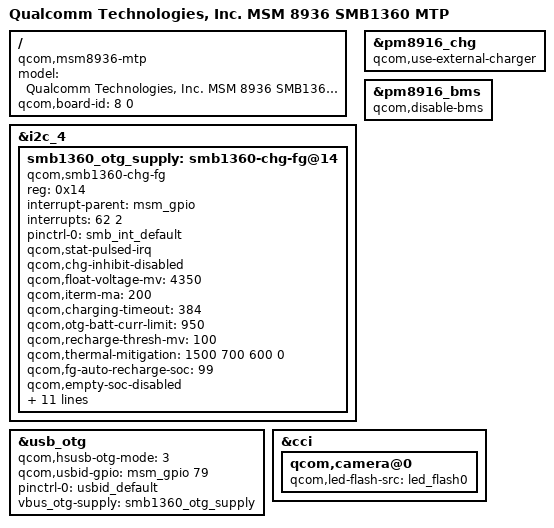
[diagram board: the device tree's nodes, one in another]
/* Copyright (c) 2014, The Linux Foundation. All rights reserved.
*
* This program is free software; you can redistribute it and/or modify
* it under the terms of the GNU General Public License version 2 and
* only version 2 as published by the Free Software Foundation.
*
* This program is distributed in the hope that it will be useful,
* but WITHOUT ANY WARRANTY; without even the implied warranty of
* MERCHANTABILITY or FITNESS FOR A PARTICULAR PURPOSE.  See the
* GNU General Public License for more details.
*/

/dts-v1/;

#include "msm8936.dtsi"
#include "msm8939-mtp.dtsi"
#include "msm8939-audio-internal_codec.dtsi"

/ {
	model = "Qualcomm Technologies, Inc. MSM 8936 SMB1360 MTP";
	compatible = "qcom,msm8936-mtp", "qcom,msm8936", "qcom,mtp";
	qcom,board-id = <8 0>;
};

&i2c_4 {
	smb1360_otg_supply: smb1360-chg-fg@14 {
/* [PLATFORM]-Mod-BEGIN by TCTNB.FLF, PR-790435, 2014/11/12, fix irq blocks booting up*/
/*
		compatible = "qcom,smb1360-chg-fg";
		reg = <0x14>;
		interrupt-parent = <&msm_gpio>;
		interrupts = <62 8>;
		pinctrl-names = "default";
		pinctrl-0 = <&smb_int_default>;
		qcom,charging-disabled;
		qcom,empty-soc-disabled;
		qcom,chg-inhibit-disabled;
		qcom,float-voltage-mv = <4200>;
		qcom,iterm-ma = <200>;
		qcom,recharge-thresh-mv = <100>;
		qcom,thermal-mitigation = <1500 700 600 0>;
		regulator-name = "smb1360_otg_vreg";
*/
        compatible = "qcom,smb1360-chg-fg";
        reg = <0x14>;
        interrupt-parent = <&msm_gpio>;
        interrupts = <62 2>;
        pinctrl-names = "default";
        pinctrl-0 = <&smb_int_default>;
        qcom,stat-pulsed-irq;
        qcom,chg-inhibit-disabled;
        qcom,float-voltage-mv = <4350>;
        qcom,iterm-ma = <200>;
        qcom,charging-timeout = <384>;
        qcom,otg-batt-curr-limit = <950>;
        qcom,recharge-thresh-mv = <100>;
        qcom,thermal-mitigation = <1500 700 600 0>;
        qcom,fg-auto-recharge-soc = <99>;
        qcom,empty-soc-disabled;
        regulator-name = "smb1360_otg_vreg";
        qcom,awake-min-soc;
        qcom,batt-profile-select;
        qcom,smb1360-vadc = <&pm8916_vadc>;
        qcom,batt-id-vref-uv = <1800000>;
        qcom,batt-id-rpullup-kohm = <100>;
        qcom,profile-a-rid-kohm = <33>;
        qcom,profile-b-rid-kohm = <91>;
        qcom,config-hard-thresholds;
        qcom,hot-bat-decidegc = <550>;
        qcom,cold-bat-decidegc = <(-150)>;
/* [PLATFORM]-Mod-END by TCTNB.FLF */
	};
};

&pm8916_chg {
	status = "ok";
	qcom,use-external-charger;
};

&pm8916_bms {
	status = "ok";
	qcom,disable-bms;
};

&usb_otg {
	qcom,hsusb-otg-mode = <3>;
	qcom,usbid-gpio = <&msm_gpio 79 0>;/*NB.THW modify 2014/11/17*/
	pinctrl-names = "default";
	pinctrl-0 = <&usbid_default>;
	vbus_otg-supply = <&smb1360_otg_supply>;
};

&cci {
	qcom,camera@0 {
		qcom,led-flash-src = <&led_flash0>;
	};
};
